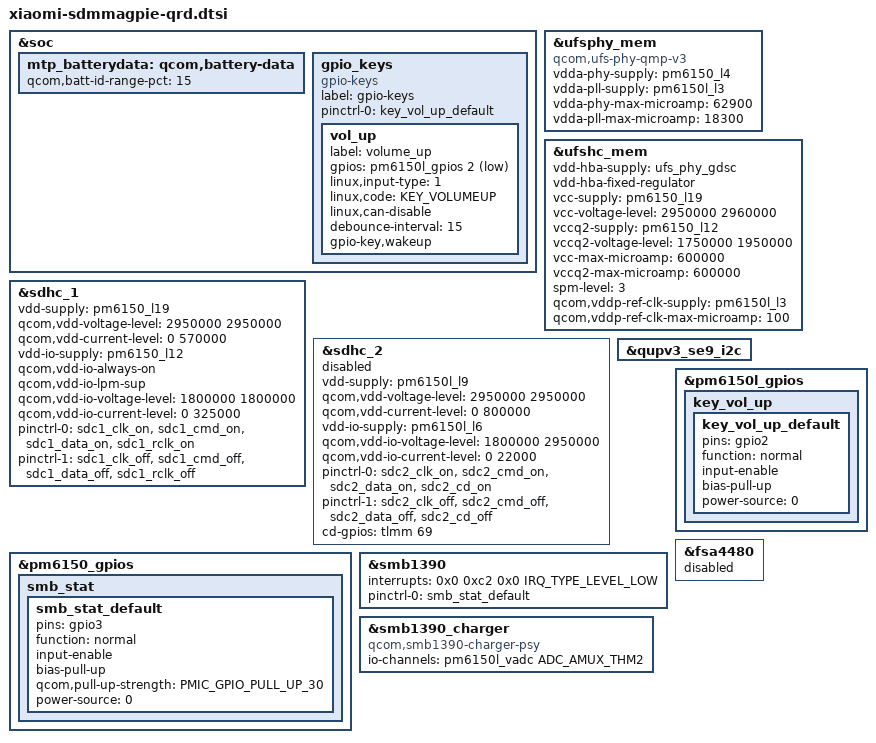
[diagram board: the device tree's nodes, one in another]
/* Copyright (c) 2018-2019, The Linux Foundation. All rights reserved.
 *
 * This program is free software; you can redistribute it and/or modify
 * it under the terms of the GNU General Public License version 2 and
 * only version 2 as published by the Free Software Foundation.
 *
 * This program is distributed in the hope that it will be useful,
 * but WITHOUT ANY WARRANTY; without even the implied warranty of
 * MERCHANTABILITY or FITNESS FOR A PARTICULAR PURPOSE.  See the
 * GNU General Public License for more details.
 */

#include <dt-bindings/gpio/gpio.h>
#include <dt-bindings/pinctrl/qcom,pmic-gpio.h>
#include <dt-bindings/iio/qcom,spmi-vadc.h>
#include <dt-bindings/input/input.h>
#include "qcom-base/sdmmagpie-thermal-overlay.dtsi"

#include "qcom-base/sdmmagpie-sde-display.dtsi"

&soc {
  mtp_batterydata: qcom,battery-data {
    qcom,batt-id-range-pct = <15>;
  };
};

&ufsphy_mem {
  compatible = "qcom,ufs-phy-qmp-v3";

  vdda-phy-supply = <&pm6150_l4>; /* 0.88v */
  vdda-pll-supply = <&pm6150l_l3>; /* 1.2v */
  vdda-phy-max-microamp = <62900>;
  vdda-pll-max-microamp = <18300>;

  status = "ok";
};

&ufshc_mem {
  vdd-hba-supply = <&ufs_phy_gdsc>;
  vdd-hba-fixed-regulator;
  vcc-supply = <&pm6150_l19>;
  vcc-voltage-level = <2950000 2960000>;
  vccq2-supply = <&pm6150_l12>;
  vccq2-voltage-level = <1750000 1950000>;
  vcc-max-microamp = <600000>;
  vccq2-max-microamp = <600000>;
  spm-level = <3>;

  qcom,vddp-ref-clk-supply = <&pm6150l_l3>;
  qcom,vddp-ref-clk-max-microamp = <100>;

  status = "ok";
};

&sdhc_1 {
  vdd-supply = <&pm6150_l19>;
  qcom,vdd-voltage-level = <2950000 2950000>;
  qcom,vdd-current-level = <0 570000>;

  vdd-io-supply = <&pm6150_l12>;
  qcom,vdd-io-always-on;
  qcom,vdd-io-lpm-sup;
  qcom,vdd-io-voltage-level = <1800000 1800000>;
  qcom,vdd-io-current-level = <0 325000>;

  pinctrl-names = "active", "sleep";
  pinctrl-0 = <&sdc1_clk_on &sdc1_cmd_on &sdc1_data_on &sdc1_rclk_on>;
  pinctrl-1 = <&sdc1_clk_off &sdc1_cmd_off &sdc1_data_off &sdc1_rclk_off>;

  status = "ok";
};

&sdhc_2 {
  vdd-supply = <&pm6150l_l9>;
  qcom,vdd-voltage-level = <2950000 2950000>;
  qcom,vdd-current-level = <0 800000>;

  vdd-io-supply = <&pm6150l_l6>;
  qcom,vdd-io-voltage-level = <1800000 2950000>;
  qcom,vdd-io-current-level = <0 22000>;

  pinctrl-names = "active", "sleep";
  pinctrl-0 = <&sdc2_clk_on  &sdc2_cmd_on &sdc2_data_on &sdc2_cd_on>;
  pinctrl-1 = <&sdc2_clk_off &sdc2_cmd_off &sdc2_data_off &sdc2_cd_off>;

  cd-gpios = <&tlmm 69 GPIO_ACTIVE_HIGH>;

  status = "disabled";
};

&qupv3_se9_i2c {
  #include "qcom-base/smb1390.dtsi"
};

&pm6150_gpios {
  smb_stat {
    smb_stat_default: smb_stat_default {
      pins = "gpio3";
      function = "normal";
      input-enable;
      bias-pull-up;
      qcom,pull-up-strength = <PMIC_GPIO_PULL_UP_30>;
      power-source = <0>;
    };
  };
};

&smb1390 {
  /delete-property/ interrupts;
  interrupts = <0x0 0xc2 0x0 IRQ_TYPE_LEVEL_LOW>;
  pinctrl-names = "default";
  pinctrl-0 = <&smb_stat_default>;
  status = "ok";
};

&smb1390_charger {
  compatible = "qcom,smb1390-charger-psy";
  io-channels = <&pm6150l_vadc ADC_AMUX_THM2>;
  io-channel-names = "cp_die_temp";
  status = "ok";
};

&pm6150l_gpios {
  key_vol_up {
    key_vol_up_default: key_vol_up_default {
      pins = "gpio2";
      function = "normal";
      input-enable;
      bias-pull-up;
      power-source = <0>;
    };
  };
};

&soc {
  gpio_keys {
    compatible = "gpio-keys";
    label = "gpio-keys";

    pinctrl-names = "default";
    pinctrl-0 = <&key_vol_up_default>;

    vol_up {
      label = "volume_up";
      gpios = <&pm6150l_gpios 2 GPIO_ACTIVE_LOW>;
      linux,input-type = <1>;
      linux,code = <KEY_VOLUMEUP>;
      linux,can-disable;
      debounce-interval = <15>;
      gpio-key,wakeup;
    };
  };
};

&fsa4480 {
  status = "disabled";
};
